# CY8C5267AXI_LP051 register map
File version: 0.1
CY8C52LP
Registers are 8-bit, read-write, no defined reset value unless marked. A register's access mark holds for its fields unless they carry their own. Offsets are from the block's base; lines under a group give offsets from that group; [hi:lo] are bit positions; {n}, {i} and the like mark numbered series; 'fields as' and 'values as' point back to an identical list; <NAME> marks a mode.

## Memory map
0x00000000 DataOut_Port5
0x00000000 DataOut_Port6
0x00000000 DataIn_Port6
0x00000000 DataIn_Port5
0x00000000 DataOut_Port1
0x00000000 UART_1 — UART
0x00000000 UART_Ctrl
0x00000000 UART_Status
0x00000000 DataIn_Port15
0x00000000 DataOut_Port15
0x00000000 DataIn_Port2
0x00000000 I2C_EEPROM
0x00000000 USBUART — USBFS
0x00000000 DataIn_Port3
0x00000000 DataOut_Port0
0x00000000 Dir_Ctl
0x00000000 DataIn_Port0
0x00000000 DataOut_Port3
0x00000000 DataIn_Port1
0x00000000 DataOut_Port4
0x00000000 DataIn_Port4
0x00000000 DataOut_Port2

## DataOut_Port5
Base 0x00000000
0x40006578 DataOut_Port5_CONTROL_REG

## DataOut_Port6
Base 0x00000000
0x40006475 DataOut_Port6_CONTROL_REG

## DataIn_Port6
Base 0x00000000
0x40006463 DataIn_Port6_STATUS_REG
0x40006483 DataIn_Port6_MASK_REG
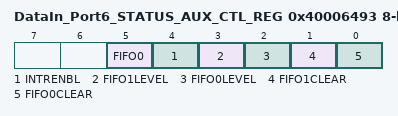
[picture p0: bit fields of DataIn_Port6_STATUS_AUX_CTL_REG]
0x40006493 DataIn_Port6_STATUS_AUX_CTL_REG
  [5] FIFO0 — FIFO0 clear
    1=ENABLED (Enable counter); 0=DISABLED (Disable counter)
  [4] INTRENBL — Enables or disables the Interrupt
    1=ENABLED (Interrupt enabled); 0=DISABLED (Interrupt disabled)
  [3] FIFO1LEVEL — FIFO level
    1=ENABLED (FIFO LVL: input mode: FIFO at least 1/2 empty; output mode: FIFO at least 1/2 full); 0=DISABLED (FIFO LVL: input mode: FIFO not full; output mode: FIFO not empty)
  [2] FIFO0LEVEL — FIFO level
    values as FIFO1LEVEL
  [1] FIFO1CLEAR — FIFO clear
    1=ENABLED (Clear FIFO state); 0=DISABLED (Normal FIFO operation)
  [0] FIFO0CLEAR — FIFO clear
    values as FIFO1CLEAR

## DataIn_Port5
Base 0x00000000
0x40006567 DataIn_Port5_STATUS_REG
0x40006587 DataIn_Port5_MASK_REG
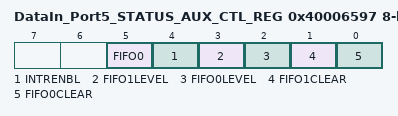
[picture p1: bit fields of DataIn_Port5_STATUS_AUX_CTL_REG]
0x40006597 DataIn_Port5_STATUS_AUX_CTL_REG
  [5] FIFO0 — FIFO0 clear
    1=ENABLED (Enable counter); 0=DISABLED (Disable counter)
  [4] INTRENBL — Enables or disables the Interrupt
    1=ENABLED (Interrupt enabled); 0=DISABLED (Interrupt disabled)
  [3] FIFO1LEVEL — FIFO level
    1=ENABLED (FIFO LVL: input mode: FIFO at least 1/2 empty; output mode: FIFO at least 1/2 full); 0=DISABLED (FIFO LVL: input mode: FIFO not full; output mode: FIFO not empty)
  [2] FIFO0LEVEL — FIFO level
    values as FIFO1LEVEL
  [1] FIFO1CLEAR — FIFO clear
    1=ENABLED (Clear FIFO state); 0=DISABLED (Normal FIFO operation)
  [0] FIFO0CLEAR — FIFO clear
    values as FIFO1CLEAR

## DataOut_Port1
Base 0x00000000
0x40006473 DataOut_Port1_CONTROL_REG

## UART_1 — UART
Base 0x00000000
0x40006441 TX_UART_1_TX_DATA — TX Data Register
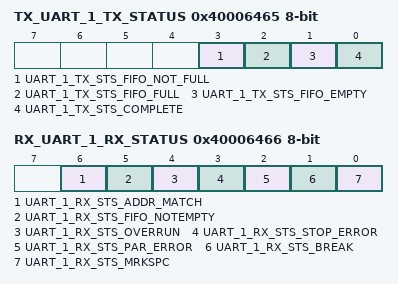
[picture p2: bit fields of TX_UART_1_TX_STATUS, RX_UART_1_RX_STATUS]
0x40006465 TX_UART_1_TX_STATUS — TX status register
  [3] UART_1_TX_STS_FIFO_NOT_FULL ro, [2] UART_1_TX_STS_FIFO_FULL ro, [1] UART_1_TX_STS_FIFO_EMPTY ro, [0] UART_1_TX_STS_COMPLETE ro
0x40006466 RX_UART_1_RX_STATUS — RX status register
  [6] UART_1_RX_STS_ADDR_MATCH ro, [5] UART_1_RX_STS_FIFO_NOTEMPTY ro, [4] UART_1_RX_STS_OVERRUN ro, [3] UART_1_RX_STS_STOP_ERROR ro, [2] UART_1_RX_STS_PAR_ERROR ro, [1] UART_1_RX_STS_BREAK ro, [0] UART_1_RX_STS_MRKSPC ro
0x40006527 RX_UART_1_RX_ADDRESS1 — RX Address1 Register
0x40006537 RX_UART_1_RX_ADDRESS2 — RX Address2 Register
0x40006547 RX_UART_1_RX_DATA — RX Data Register

## UART_Ctrl
Base 0x00000000
0x40006477 UART_Ctrl_CONTROL_REG

## UART_Status
Base 0x00000000
0x40006564 UART_Status_STATUS_REG
0x40006584 UART_Status_MASK_REG
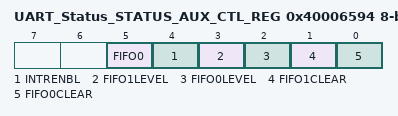
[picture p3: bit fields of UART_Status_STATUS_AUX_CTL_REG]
0x40006594 UART_Status_STATUS_AUX_CTL_REG
  [5] FIFO0 — FIFO0 clear
    1=ENABLED (Enable counter); 0=DISABLED (Disable counter)
  [4] INTRENBL — Enables or disables the Interrupt
    1=ENABLED (Interrupt enabled); 0=DISABLED (Interrupt disabled)
  [3] FIFO1LEVEL — FIFO level
    1=ENABLED (FIFO LVL: input mode: FIFO at least 1/2 empty; output mode: FIFO at least 1/2 full); 0=DISABLED (FIFO LVL: input mode: FIFO not full; output mode: FIFO not empty)
  [2] FIFO0LEVEL — FIFO level
    values as FIFO1LEVEL
  [1] FIFO1CLEAR — FIFO clear
    1=ENABLED (Clear FIFO state); 0=DISABLED (Normal FIFO operation)
  [0] FIFO0CLEAR — FIFO clear
    values as FIFO1CLEAR
